# LargeDummyDevice register map
File version: 1.0
Registers are 32-bit, read-write, no defined reset value unless marked. A register's access mark holds for its fields unless they carry their own. Offsets are from the block's base; [hi:lo] are bit positions.

## PERIPHERAL_64
Base 0x4003F000
0x04 REG_1 — Register 1
  [33:30] FIELD_4, [33:29] FIELD_23, [29:28] FIELD_9, [30:28] FIELD_17, [31:28] FIELD_25, [28:26] FIELD_10, [26:25] FIELD_22, [22:21] FIELD_14, [17] FIELD_24, [16] FIELD_2, [16:15] FIELD_12, [13] FIELD_11, [16:12] FIELD_7, [11] FIELD_5, [11] FIELD_15, [14:10] FIELD_1, [8:7] FIELD_21, [6:4] FIELD_18, [4:3] FIELD_6, [4:3] FIELD_16, [7:3] FIELD_20, [6:2] FIELD_3, [3:2] FIELD_8, [3:1] FIELD_13, [4:1] FIELD_19
0x08 REG_2 — Register 2
  [34:30] FIELD_4, [30] FIELD_7, [30:29] FIELD_12, [30:27] FIELD_3, [27:24] FIELD_5, [27:24] FIELD_10, [21:17] FIELD_2, [16:12] FIELD_6, [13:10] FIELD_1, [10:9] FIELD_11, [7:6] FIELD_9, [6:4] FIELD_8
0x0C REG_3 — Register 3
  [7:4] FIELD_1
0x10 REG_4 — Register 4
  [33:30] FIELD_13, [32:29] FIELD_6, [30:29] FIELD_9, [27] FIELD_8, [30:26] FIELD_15, [21:17] FIELD_5, [16:13] FIELD_2, [14:12] FIELD_11, [14:12] FIELD_14, [14:10] FIELD_7, [8] FIELD_10, [11:7] FIELD_4, [7:6] FIELD_12, [3] FIELD_1, [7:3] FIELD_3
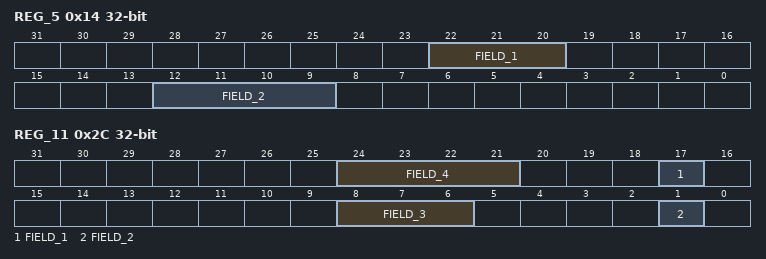
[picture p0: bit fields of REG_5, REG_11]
0x14 REG_5 — Register 5
  [22:20] FIELD_1, [12:9] FIELD_2
0x18 REG_6 — Register 6
  [31:27] FIELD_7, [22:20] FIELD_5, [18:17] FIELD_4, [15:13] FIELD_1, [15:13] FIELD_3, [9] FIELD_2, [9:7] FIELD_6, [5:1] FIELD_8
0x1C REG_7 — Register 7
  [28] FIELD_9, [28:27] FIELD_4, [29:27] FIELD_10, [27:26] FIELD_11, [26:25] FIELD_5, [28:24] FIELD_8, [11:7] FIELD_1, [7:5] FIELD_6, [4] FIELD_2, [1] FIELD_3, [1:0] FIELD_7
0x20 REG_8 — Register 8
  [28] FIELD_11, [27] FIELD_6, [29:27] FIELD_9, [24] FIELD_7, [24] FIELD_17, [25:22] FIELD_1, [26:22] FIELD_14, [19:16] FIELD_16, [19:15] FIELD_12, [19:15] FIELD_15, [18:14] FIELD_18, [14:13] FIELD_3, [14:12] FIELD_5, [10:6] FIELD_8, [7:5] FIELD_4, [6:5] FIELD_13, [5:4] FIELD_10, [0] FIELD_2
0x24 REG_9 — Register 9
  [32:29] FIELD_8, [30:29] FIELD_11, [29] FIELD_12, [31:28] FIELD_3, [27:23] FIELD_10, [25:22] FIELD_17, [24:20] FIELD_1, [21:19] FIELD_15, [21:19] FIELD_16, [19:17] FIELD_2, [15:12] FIELD_4, [14:12] FIELD_9, [14:12] FIELD_13, [14:11] FIELD_5, [10] FIELD_7, [6:5] FIELD_14, [3:1] FIELD_6, [5:1] FIELD_18
0x28 REG_10 — Register 10
  [30:29] FIELD_11, [26:23] FIELD_10, [19:18] FIELD_9, [19:17] FIELD_4, [18:16] FIELD_8, [13] FIELD_7, [15:12] FIELD_5, [15:12] FIELD_12, [13:10] FIELD_3, [10:6] FIELD_1, [5:2] FIELD_6, [0] FIELD_2
0x2C REG_11 — Register 11
  [24:21] FIELD_4, [17] FIELD_1, [8:6] FIELD_3, [1] FIELD_2
0x30 REG_12 — Register 12
  [35:31] FIELD_11, [31:30] FIELD_4, [34:30] FIELD_25, [30:28] FIELD_19, [28] FIELD_23, [26:25] FIELD_15, [24:21] FIELD_27, [20:19] FIELD_6, [20:18] FIELD_3, [21:18] FIELD_5, [19:18] FIELD_7, [19:17] FIELD_26, [17:16] FIELD_13, [16] FIELD_18, [19:16] FIELD_22, [18:15] FIELD_2, [16:15] FIELD_14, [15] FIELD_28, [13] FIELD_16, [14:13] FIELD_21, [13:11] FIELD_20, [10:9] FIELD_8, [8] FIELD_1, [10:8] FIELD_12, [9:5] FIELD_17, [6:3] FIELD_10, [2:1] FIELD_9, [3:1] FIELD_24
0x34 REG_13 — Register 13
  [35:31] FIELD_5, [35:31] FIELD_12, [32:29] FIELD_3, [32:28] FIELD_2, [29:28] FIELD_8, [29:25] FIELD_13, [27:23] FIELD_14, [24:20] FIELD_7, [19:16] FIELD_15, [15:12] FIELD_6, [12:11] FIELD_4, [11:8] FIELD_11, [7] FIELD_1, [5] FIELD_9, [5:3] FIELD_16, [2] FIELD_10
0x38 REG_14 — Register 14
  [34:31] FIELD_14, [31:29] FIELD_7, [29] FIELD_17, [32:29] FIELD_23, [30:28] FIELD_15, [30:27] FIELD_19, [28:26] FIELD_13, [26:23] FIELD_12, [25:22] FIELD_8, [20:17] FIELD_21, [17:16] FIELD_10, [18:14] FIELD_16, [14:13] FIELD_5, [13] FIELD_26, [11] FIELD_6, [11:10] FIELD_11, [12:10] FIELD_18, [10] FIELD_25, [13:9] FIELD_3, [12:8] FIELD_1, [8] FIELD_2, [11:8] FIELD_9, [6] FIELD_24, [4] FIELD_20, [3] FIELD_22, [5:1] FIELD_4
0x3C REG_15 — Register 15
  [30] FIELD_3, [30:29] FIELD_4, [28:24] FIELD_2, [27:23] FIELD_1
0x40 REG_16 — Register 16
  [32:28] FIELD_9, [27:25] FIELD_3, [21] FIELD_5, [16:14] FIELD_4, [17:14] FIELD_8, [10:9] FIELD_11, [9:8] FIELD_2, [8:7] FIELD_7, [8:6] FIELD_10, [8:5] FIELD_6, [3:0] FIELD_1
0x44 REG_17 — Register 17
  [24] FIELD_1
0x48 REG_18 — Register 18
  [33:30] FIELD_1, [28] FIELD_11, [27:23] FIELD_6, [26:22] FIELD_10, [19] FIELD_14, [14:12] FIELD_3, [16:12] FIELD_8, [12] FIELD_16, [11:10] FIELD_7, [10] FIELD_13, [13:9] FIELD_4, [9] FIELD_5, [7] FIELD_9, [4] FIELD_2, [4:3] FIELD_12, [4:2] FIELD_15
0x4C REG_19 — Register 19
  [34:31] FIELD_10, [31] FIELD_17, [33:30] FIELD_12, [32:30] FIELD_25, [32:28] FIELD_16, [32:28] FIELD_20, [30:27] FIELD_7, [30:27] FIELD_9, [28:26] FIELD_3, [27:25] FIELD_18, [24] FIELD_21, [25:22] FIELD_4, [22:20] FIELD_11, [19:15] FIELD_8, [18:15] FIELD_22, [15:13] FIELD_13, [14:12] FIELD_24, [13:11] FIELD_26, [9:8] FIELD_19, [8] FIELD_23, [7] FIELD_6, [9:6] FIELD_14, [10:6] FIELD_15, [5:3] FIELD_1, [3:2] FIELD_2, [4:1] FIELD_5
0x50 REG_20 — Register 20
  [34:30] FIELD_18, [27] FIELD_15, [30:27] FIELD_16, [25] FIELD_13, [23:21] FIELD_8, [22:20] FIELD_5, [24:20] FIELD_10, [21:19] FIELD_9, [19:17] FIELD_1, [15:12] FIELD_2, [13:11] FIELD_12, [13:10] FIELD_3, [7] FIELD_7, [11:7] FIELD_14, [9:7] FIELD_19, [8:5] FIELD_17, [4:3] FIELD_11, [3:2] FIELD_4, [2] FIELD_6
